VERSION ""

NS_ :

BS_:

BU_: HI14RX_J1939

BO_ 2365538568 PGN65345: 8 HI14RX_J1939
 SG_ PGN65345_RES : 32|32@1- (1,0) [0|0] "" Vector__XXX
 SG_ Yaw : 0|32@1- (0.001,0) [0|360] "deg" Vector__XXX

BO_ 2365540872 PGN65354: 8 HI14RX_J1939
 SG_ Angle_X_Dual_Axis : 0|32@1- (0.001,0) [-180|360] "deg" Vector__XXX
 SG_ Angle_Y_Dual_Axis : 32|32@1- (0.001,0) [-180|360] "deg" Vector__XXX

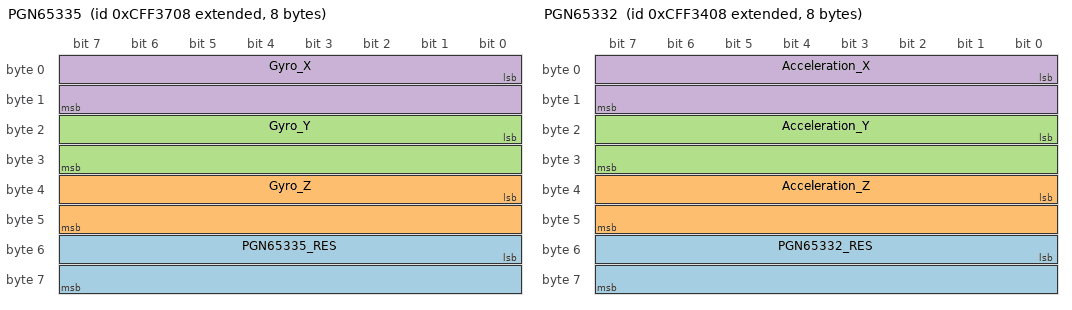
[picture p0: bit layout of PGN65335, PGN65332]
BO_ 2365536008 PGN65335: 8 HI14RX_J1939
 SG_ PGN65335_RES : 48|16@1- (1,0) [0|0] "" Vector__XXX
 SG_ Gyro_Z : 32|16@1- (0.061035,0) [-2000|2000] "deg/s" Vector__XXX
 SG_ Gyro_Y : 16|16@1- (0.061035,0) [-2000|2000] "deg/s" Vector__XXX
 SG_ Gyro_X : 0|16@1- (0.061035,0) [-2000|2000] "deg/s" Vector__XXX

BO_ 2365535240 PGN65332: 8 HI14RX_J1939
 SG_ PGN65332_RES : 48|16@1- (1,0) [0|0] "" Vector__XXX
 SG_ Acceleration_Z : 32|16@1- (0.00048828,0) [-4000|4000] "G" Vector__XXX
 SG_ Acceleration_Y : 16|16@1- (0.00048828,0) [-4000|4000] "G" Vector__XXX
 SG_ Acceleration_X : 0|16@1- (0.00048828,0) [-4000|4000] "G" Vector__XXX

BA_DEF_ BO_  "FrameFormat" ENUM  "StandardCAN","ExtendedCAN","reserved","J1939PG";
BA_DEF_ BO_  "SingleFrame" INT 0 1;
BA_DEF_  "Manufacturer" STRING ;
BA_DEF_ SG_  "SigType" ENUM  "Default","Range","RangeSigned","ASCII","Discrete","Control","ReferencePGN","DTC","StringDelimiter","StringLength","StringLengthControl","MessageCounter","MessageChecksum";
BA_DEF_ SG_  "GenSigEVName" STRING ;
BA_DEF_ SG_  "GenSigILSupport" ENUM  "No","Yes";
BA_DEF_ SG_  "GenSigSendType" ENUM  "Cyclic","OnWrite","OnWriteWithRepetition","OnChange","OnChangeWithRepetition","IfActive","IfActiveWithRepetition","NoSigSendType";
BA_DEF_ SG_  "GenSigInactiveValue" INT 0 0;
BA_DEF_ BO_  "GenMsgILSupport" ENUM  "No","Yes";
BA_DEF_ BU_  "NmStationAddress" INT 0 255;
BA_DEF_ BO_  "GenMsgSendType" ENUM  "cyclic","NotUsed","IfActive","NotUsed","NotUsed","NotUsed","NotUsed","NotUsed","noMsgSendType";
BA_DEF_ BO_  "GenMsgRequestable" INT 0 1;
BA_DEF_ BO_  "GenMsgCycleTime" INT 0 3600000;
BA_DEF_  "DBName" STRING ;
BA_DEF_  "BusType" STRING ;
BA_DEF_  "ProtocolType" STRING ;
BA_DEF_ BO_  "VFrameFormat" ENUM  "StandardCAN","ExtendedCAN","reserved","J1939PG";
BA_DEF_DEF_  "FrameFormat" "J1939PG";
BA_DEF_DEF_  "SingleFrame" 1;
BA_DEF_DEF_  "Manufacturer" "Vector";
BA_DEF_DEF_  "SigType" "Default";
BA_DEF_DEF_  "GenSigEVName" "Env@Nodename_@Signame";
BA_DEF_DEF_  "GenSigILSupport" "Yes";
BA_DEF_DEF_  "GenSigSendType" "NoSigSendType";
BA_DEF_DEF_  "GenSigInactiveValue" 0;
BA_DEF_DEF_  "GenMsgILSupport" "Yes";
BA_DEF_DEF_  "NmStationAddress" 254;
BA_DEF_DEF_  "GenMsgSendType" "noMsgSendType";
BA_DEF_DEF_  "GenMsgRequestable" 1;
BA_DEF_DEF_  "GenMsgCycleTime" 0;
BA_DEF_DEF_  "DBName" "";
BA_DEF_DEF_  "BusType" "CAN";
BA_DEF_DEF_  "ProtocolType" "J1939";
BA_DEF_DEF_  "VFrameFormat" "J1939PG";
BA_ "DBName" "HI14RX_J1939";
BA_ "NmStationAddress" BU_ HI14RX_J1939 8;
BA_ "GenMsgCycleTime" BO_ 2365540872 10;
BA_ "GenMsgCycleTime" BO_ 2365536008 10;
BA_ "GenMsgCycleTime" BO_ 2365535240 10;
BA_ "GenSigInactiveValue" SG_ 2365540872 Angle_X_Dual_Axis 0.0076293945313;
BA_ "GenSigInactiveValue" SG_ 2365540872 Angle_Y_Dual_Axis 0.0076293945313;
BA_ "GenSigInactiveValue" SG_ 2365536008 Gyro_Z 0.0076293945313;
BA_ "GenSigInactiveValue" SG_ 2365536008 Gyro_Y 0.0076293945313;
BA_ "GenSigInactiveValue" SG_ 2365536008 Gyro_X 0.0076293945313;
BA_ "GenSigInactiveValue" SG_ 2365535240 Acceleration_Z 0.0076293945313;
BA_ "GenSigInactiveValue" SG_ 2365535240 Acceleration_Y 0.0076293945313;
BA_ "GenSigInactiveValue" SG_ 2365535240 Acceleration_X 0.0076293945313;
